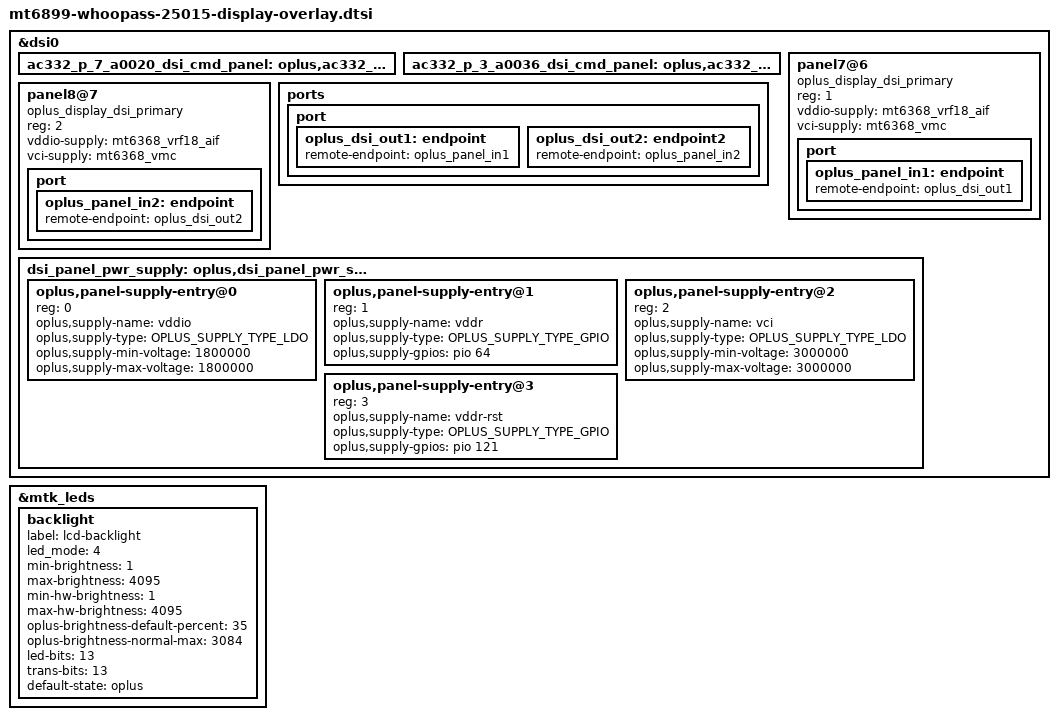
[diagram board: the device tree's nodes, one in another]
#include "mt6899-dsi-display-conf.h"
#include "ac332-p-7-a0020-dsi-cmd-panel-ext-params.dtsi"
#include "ac332-p-3-a0036-dsi-cmd-panel-ext-params.dtsi"

&dsi0 {
	ac332_p_7_a0020_dsi_cmd_panel: oplus,ac332_p_7_a0020_dsi_cmd_panel {};
	ac332_p_3_a0036_dsi_cmd_panel: oplus,ac332_p_3_a0036_dsi_cmd_panel {};
};

#include "ac332-p-7-a0020-dsi-cmd-panel-cmd.dtsi"
#include "ac332-p-3-a0036-dsi-cmd-panel-cmd.dtsi"

&mtk_leds {
	status = "okay";

	backlight {
		label = "lcd-backlight";
		led_mode = <4>;
		min-brightness = <1>;
		max-brightness = <4095>;
		min-hw-brightness = <1>;
		max-hw-brightness = <4095>;
		oplus-brightness-default-percent = <35>;
		oplus-brightness-normal-max = <3084>;
		led-bits = <13>;
		trans-bits = <13>;
		default-state = "oplus";
	};
};

&dsi0 {
	status = "okay";
	#address-cells = <1>;
	#size-cells = <0>;
	/* choose second panel which support spr */
	/* choose MTK SPR IP */
	panel7@6 {
		compatible = "oplus_display_dsi_primary";
		reg = <1>;
		vddio-supply = <&mt6368_vrf18_aif>;
		vci-supply = <&mt6368_vmc>;
		pinctrl-names = "default";
		port {
			oplus_panel_in1: endpoint {
				remote-endpoint = <&oplus_dsi_out1>;
			};
		};
	};

	panel8@7 {
		compatible = "oplus_display_dsi_primary";
		reg = <2>;
		vddio-supply = <&mt6368_vrf18_aif>;
		vci-supply = <&mt6368_vmc>;
		pinctrl-names = "default";
		port {
			oplus_panel_in2: endpoint {
				remote-endpoint = <&oplus_dsi_out2>;
			};
		};
	};

	ports {
		port {
			oplus_dsi_out1: endpoint {
				remote-endpoint = <&oplus_panel_in1>;
			};
			oplus_dsi_out2: endpoint2 {
				remote-endpoint = <&oplus_panel_in2>;
			};
		};
	};
};

&dsi0 {
	dsi_panel_pwr_supply: oplus,dsi_panel_pwr_supply {
		oplus,panel-supply-entry@0 {
			reg = <0>;
			oplus,supply-name = "vddio";
			oplus,supply-type = <OPLUS_SUPPLY_TYPE_LDO>;
			oplus,supply-min-voltage = <1800000>;
			oplus,supply-max-voltage = <1800000>;
		};
		oplus,panel-supply-entry@1 {
			reg = <1>;
			oplus,supply-name = "vddr";
			oplus,supply-type = <OPLUS_SUPPLY_TYPE_GPIO>;
			oplus,supply-gpios = <&pio 64 0>;
		};
		oplus,panel-supply-entry@2 {
			reg = <2>;
			oplus,supply-name = "vci";
			oplus,supply-type = <OPLUS_SUPPLY_TYPE_LDO>;
			oplus,supply-min-voltage = <3000000>;
			oplus,supply-max-voltage = <3000000>;
		};
		oplus,panel-supply-entry@3 {
			reg = <3>;
			oplus,supply-name = "vddr-rst";
			oplus,supply-type = <OPLUS_SUPPLY_TYPE_GPIO>;
			oplus,supply-gpios = <&pio 121 0>;
		};
	};
};
